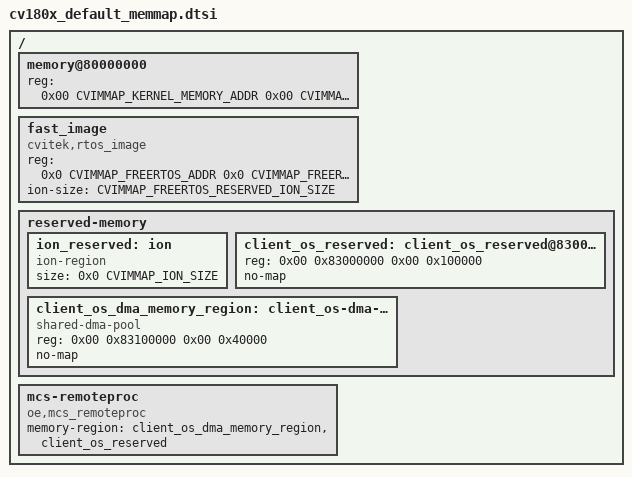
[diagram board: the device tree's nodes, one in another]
/ {
	memory@80000000 {
		device_type = "memory";
		reg = <0x00 CVIMMAP_KERNEL_MEMORY_ADDR 0x00 CVIMMAP_KERNEL_MEMORY_SIZE>;
	};


	fast_image {
		compatible = "cvitek,rtos_image";
		reg-names = "rtos_region";
		reg = <0x0 CVIMMAP_FREERTOS_ADDR 0x0 CVIMMAP_FREERTOS_SIZE>;
		ion-size = <CVIMMAP_FREERTOS_RESERVED_ION_SIZE>;	//reserved ion size for freertos
	};

	reserved-memory {
		#size-cells = <0x2>;
		#address-cells = <0x2>;
		ranges;

		ion_reserved: ion {
			compatible = "ion-region";
			size = <0x0 CVIMMAP_ION_SIZE>;
		};
	};
	reserved-memory {
	            #address-cells = <0x02>;
	            #size-cells = <0x02>;
	            ranges;	
	            client_os_reserved: client_os_reserved@83000000 {
	                reg = <0x00 0x83000000 0x00 0x100000>;
	                no-map;
	            };
	
	            client_os_dma_memory_region: client_os-dma-memory@83100000 {
	                compatible = "shared-dma-pool";
	                reg = <0x00 0x83100000 0x00 0x40000>;
	                no-map;
	            };
	 };
	
	mcs-remoteproc {
	            compatible = "oe,mcs_remoteproc";
	            memory-region = <&client_os_dma_memory_region>,
	                            <&client_os_reserved>;
	};
};
